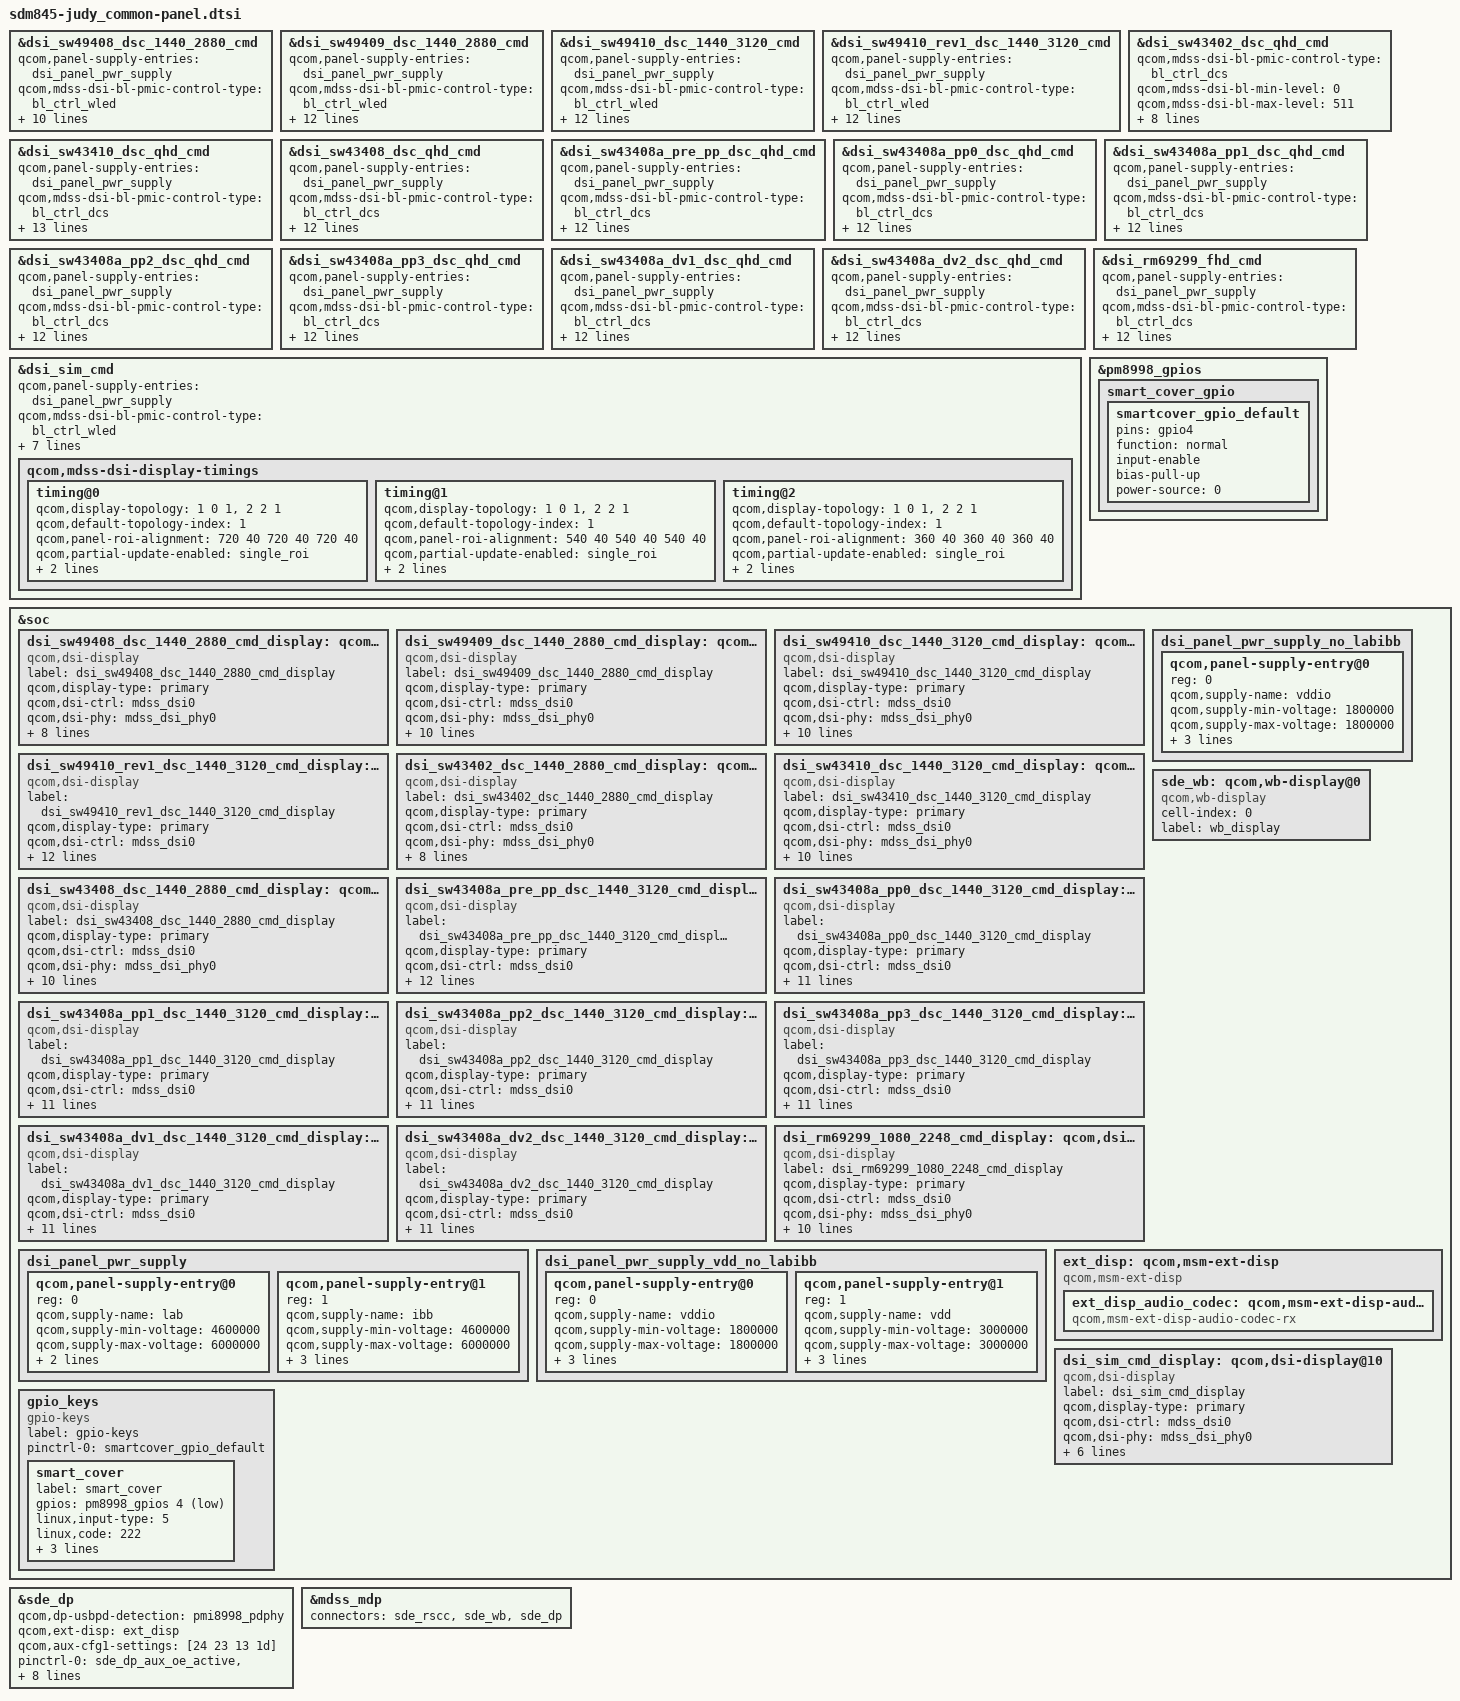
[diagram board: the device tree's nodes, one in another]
/* Copyright (c) 2017, The Linux Foundation. All rights reserved.
 *
 * This program is free software; you can redistribute it and/or modify
 * it under the terms of the GNU General Public License version 2 and
 * only version 2 as published by the Free Software Foundation.
 *
 * This program is distributed in the hope that it will be useful,
 * but WITHOUT ANY WARRANTY; without even the implied warranty of
 * MERCHANTABILITY or FITNESS FOR A PARTICULAR PURPOSE.  See the
 * GNU General Public License for more details.
 */

#include "../dsi-panel-sw49408-dsc-1440-2880-cmd.dtsi"
#include "../dsi-panel-sw49409-dsc-1440-2880-cmd.dtsi"
#include "../dsi-panel-sw49410-dsc-1440-3120-cmd.dtsi"
#include "../dsi-panel-sw49410-rev1-dsc-1440-3120-cmd.dtsi"
#include "../dsi-panel-sw43402-dsc-qhd-cmd.dtsi"
#include "../dsi-panel-sw43408-dsc-qhd-cmd.dtsi"
#include "../dsi-panel-sw43408a-pre-pp-dsc-qhd-cmd.dtsi"
#include "../dsi-panel-sw43408a-pp0-dsc-qhd-cmd.dtsi"
#include "../dsi-panel-sw43408a-pp1-dsc-qhd-cmd.dtsi"
#include "../dsi-panel-sw43408a-pp2-dsc-qhd-cmd.dtsi"
#include "../dsi-panel-sw43408a-pp3-dsc-qhd-cmd.dtsi"
#include "../dsi-panel-sw43408a-dv1-dsc-qhd-cmd.dtsi"
#include "../dsi-panel-sw43408a-dv2-dsc-qhd-cmd.dtsi"
#include "../dsi-panel-sw43410-dsc-qhd-cmd.dtsi"
#include "../dsi-panel-rm69299-fhd-cmd.dtsi"
#include "../../../qcom/dsi-panel-sim-cmd.dtsi"

#include <dt-bindings/clock/mdss-10nm-pll-clk.h>

&dsi_sw49408_dsc_1440_2880_cmd {
	qcom,panel-supply-entries = <&dsi_panel_pwr_supply>;
	qcom,mdss-dsi-bl-pmic-control-type = "bl_ctrl_wled";
	qcom,mdss-dsi-bl-min-level = <1>;
	qcom,mdss-dsi-bl-max-level = <4095>;
	qcom,platform-reset-gpio = <&tlmm 6 0>;
	lge,man-name = "LGD";
	lge,ddic-name = "sw49408";
	lge,panel-pins =
		<&tlmm 2 0>,  // vddio
		<&tlmm 116 0>; // vpnl
	lge,panel-on-pin-seq = <0 1 2>, <1 1 5>;
	lge,panel-off-pin-seq = <1 0 5>, <0 0 0>;
	lge,use-labibb;
	lge,default-brightness = <144>;
};

&dsi_sw49409_dsc_1440_2880_cmd {
	qcom,panel-supply-entries = <&dsi_panel_pwr_supply>;
	qcom,mdss-dsi-bl-pmic-control-type = "bl_ctrl_wled";
	qcom,mdss-dsi-bl-min-level = <1>;
	qcom,mdss-dsi-bl-max-level = <4095>;
	qcom,mdss-brightness-max-level = <255>;
	qcom,platform-reset-gpio = <&tlmm 6 0>;
	lge,panel-pins =
		<&tlmm 2 0>;  // vddio
	lge,man-name = "LGD";
	lge,ddic-name = "sw49409";
	lge,panel-on-pin-seq = <0 1 6>;
	lge,panel-off-pin-seq = <0 0 0>;
	lge,use-labibb;
	lge,reset-after-ddvd;
	lge,default-brightness = <144>;
};

&dsi_sw49410_dsc_1440_3120_cmd {
	qcom,panel-supply-entries = <&dsi_panel_pwr_supply>;
	qcom,mdss-dsi-bl-pmic-control-type = "bl_ctrl_wled";
	qcom,mdss-dsi-bl-min-level = <1>;
	qcom,mdss-dsi-bl-max-level = <4095>;
	qcom,mdss-brightness-max-level = <255>;
	qcom,platform-reset-gpio = <&tlmm 6 0>;
	lge,panel-pins =
		<&tlmm 2 0>;  // vddio
	lge,man-name = "LGD";
	lge,ddic-name = "sw49410";
	lge,panel-on-pin-seq = <0 1 6>;
	lge,panel-off-pin-seq = <0 0 0>;
	lge,use-labibb;
	lge,reset-after-ddvd;
	lge,default-brightness = <144>;
};

&dsi_sw49410_rev1_dsc_1440_3120_cmd {
	qcom,panel-supply-entries = <&dsi_panel_pwr_supply>;
	qcom,mdss-dsi-bl-pmic-control-type = "bl_ctrl_wled";
	qcom,mdss-dsi-bl-min-level = <1>;
	qcom,mdss-dsi-bl-max-level = <4095>;
	qcom,mdss-brightness-max-level = <255>;
	qcom,platform-reset-gpio = <&tlmm 6 0>;
	lge,panel-pins =
		<&tlmm 2 0>;  // vddio
	lge,man-name = "LGD";
	lge,ddic-name = "sw49410_rev1";
	lge,panel-on-pin-seq = <0 1 6>;
	lge,panel-off-pin-seq = <0 0 0>;
	lge,use-labibb;
	lge,reset-after-ddvd;
	lge,default-brightness = <144>;
};

&dsi_sw43402_dsc_qhd_cmd {
	qcom,mdss-dsi-bl-pmic-control-type = "bl_ctrl_dcs";
	qcom,mdss-dsi-bl-min-level = <0>;
	qcom,mdss-dsi-bl-max-level = <511>;
	qcom,mdss-brightness-max-level = <511>;
	qcom,platform-reset-gpio = <&tlmm 6 0>;
	lge,man-name = "LGD";
	lge,ddic-name = "sw43402";
	lge,panel-pins =
		<&tlmm 2 0>,  // vddio
		<&tlmm 113 0>; // vpnl
	lge,panel-on-pin-seq = <0 1 2>, <1 1 5>;
	lge,panel-off-pin-seq = <1 0 5>, <0 0 0>;
	lge,default-brightness = <158>;
};

&dsi_sw43410_dsc_qhd_cmd {
	qcom,panel-supply-entries = <&dsi_panel_pwr_supply>;
	qcom,mdss-dsi-bl-pmic-control-type = "bl_ctrl_dcs";
	qcom,mdss-dsi-bl-min-level = <10>;
	qcom,mdss-dsi-bl-max-level = <511>;
	qcom,mdss-brightness-max-level = <511>;
	qcom,platform-reset-gpio = <&tlmm 6 0>;
	lge,man-name = "LGD";
	lge,ddic-name = "sw43410";
	lge,panel-pins =
		<&tlmm 2 0>,  // vddio
		<&tlmm 113 0>; // vpnl
	lge,panel-on-pin-seq = <0 1 2>, <1 1 5>;
	lge,panel-off-pin-seq = <1 0 5>, <0 0 0>;
	lge,use-labibb;
	lge,dcs-brightness-bigendian;
	lge,reset-after-ddvd;
	lge,default-brightness = <158>;
};

&dsi_sw43408_dsc_qhd_cmd {
	qcom,panel-supply-entries = <&dsi_panel_pwr_supply>;
	qcom,mdss-dsi-bl-pmic-control-type = "bl_ctrl_dcs";
	qcom,mdss-dsi-bl-min-level = <10>;
	qcom,mdss-dsi-bl-max-level = <511>;
	qcom,mdss-brightness-max-level = <511>;
	qcom,platform-reset-gpio = <&tlmm 6 0>;
	lge,man-name = "LGD";
	lge,ddic-name = "sw43408";
	lge,panel-pins =
		<&tlmm 8 0>,  // vddio
		<&tlmm 113 0>; // vpnl
	lge,panel-on-pin-seq = <0 1 2>, <1 1 5>;
	lge,panel-off-pin-seq = <1 0 5>, <0 0 0>;
	lge,use-labibb;
	lge,dcs-brightness-bigendian;
	lge,default-brightness = <144>;
};

&dsi_sw43408a_pre_pp_dsc_qhd_cmd {
	qcom,panel-supply-entries = <&dsi_panel_pwr_supply>;
	qcom,mdss-dsi-bl-pmic-control-type = "bl_ctrl_dcs";
	qcom,mdss-dsi-bl-min-level = <10>;
	qcom,mdss-dsi-bl-max-level = <511>;
	qcom,mdss-brightness-max-level = <511>;
	qcom,platform-reset-gpio = <&tlmm 6 0>;
	lge,man-name = "LGD";
	lge,ddic-name = "sw43408a";
	lge,panel-pins =
		<&tlmm 2 0>,  // vddio
		<&tlmm 113 0>; // vpnl
	lge,panel-on-pin-seq = <0 1 2>, <1 1 5>;
	lge,panel-off-pin-seq = <1 0 5>, <0 0 0>;
	lge,use-labibb;
	lge,dcs-brightness-bigendian;
	lge,default-brightness = <144>;
};

&dsi_sw43408a_pp0_dsc_qhd_cmd {
	qcom,panel-supply-entries = <&dsi_panel_pwr_supply>;
	qcom,mdss-dsi-bl-pmic-control-type = "bl_ctrl_dcs";
	qcom,mdss-dsi-bl-min-level = <10>;
	qcom,mdss-dsi-bl-max-level = <511>;
	qcom,mdss-brightness-max-level = <511>;
	qcom,platform-reset-gpio = <&tlmm 6 0>;
	lge,man-name = "LGD";
	lge,ddic-name = "sw43408a";
	lge,panel-pins =
		<&tlmm 2 0>,  // vddio
		<&tlmm 113 0>; // vpnl
	lge,panel-on-pin-seq = <0 1 2>, <1 1 5>;
	lge,panel-off-pin-seq = <1 0 5>, <0 0 0>;
	lge,use-labibb;
	lge,dcs-brightness-bigendian;
	lge,default-brightness = <144>;
};

&dsi_sw43408a_pp1_dsc_qhd_cmd {
	qcom,panel-supply-entries = <&dsi_panel_pwr_supply>;
	qcom,mdss-dsi-bl-pmic-control-type = "bl_ctrl_dcs";
	qcom,mdss-dsi-bl-min-level = <10>;
	qcom,mdss-dsi-bl-max-level = <511>;
	qcom,mdss-brightness-max-level = <511>;
	qcom,platform-reset-gpio = <&tlmm 6 0>;
	lge,man-name = "LGD";
	lge,ddic-name = "sw43408a";
	lge,panel-pins =
		<&tlmm 2 0>,  // vddio
		<&tlmm 113 0>; // vpnl
	lge,panel-on-pin-seq = <0 1 2>, <1 1 5>;
	lge,panel-off-pin-seq = <1 0 5>, <0 0 0>;
	lge,use-labibb;
	lge,dcs-brightness-bigendian;
	lge,default-brightness = <144>;
};

&dsi_sw43408a_pp2_dsc_qhd_cmd {
	qcom,panel-supply-entries = <&dsi_panel_pwr_supply>;
	qcom,mdss-dsi-bl-pmic-control-type = "bl_ctrl_dcs";
	qcom,mdss-dsi-bl-min-level = <10>;
	qcom,mdss-dsi-bl-max-level = <511>;
	qcom,mdss-brightness-max-level = <511>;
	qcom,platform-reset-gpio = <&tlmm 6 0>;
	lge,man-name = "LGD";
	lge,ddic-name = "sw43408a";
	lge,panel-pins =
		<&tlmm 2 0>,  // vddio
		<&tlmm 113 0>; // vpnl
	lge,panel-on-pin-seq = <0 1 2>, <1 1 5>;
	lge,panel-off-pin-seq = <1 0 5>, <0 0 0>;
	lge,use-labibb;
	lge,dcs-brightness-bigendian;
	lge,default-brightness = <144>;
};

&dsi_sw43408a_pp3_dsc_qhd_cmd {
	qcom,panel-supply-entries = <&dsi_panel_pwr_supply>;
	qcom,mdss-dsi-bl-pmic-control-type = "bl_ctrl_dcs";
	qcom,mdss-dsi-bl-min-level = <10>;
	qcom,mdss-dsi-bl-max-level = <511>;
	qcom,mdss-brightness-max-level = <511>;
	qcom,platform-reset-gpio = <&tlmm 6 0>;
	lge,man-name = "LGD";
	lge,ddic-name = "sw43408a";
	lge,panel-pins =
		<&tlmm 2 0>,  // vddio
		<&tlmm 113 0>; // vpnl
	lge,panel-on-pin-seq = <0 1 2>, <1 1 5>;
	lge,panel-off-pin-seq = <1 0 5>, <0 0 0>;
	lge,use-labibb;
	lge,dcs-brightness-bigendian;
	lge,default-brightness = <144>;
};

&dsi_sw43408a_dv1_dsc_qhd_cmd {
	qcom,panel-supply-entries = <&dsi_panel_pwr_supply>;
	qcom,mdss-dsi-bl-pmic-control-type = "bl_ctrl_dcs";
	qcom,mdss-dsi-bl-min-level = <10>;
	qcom,mdss-dsi-bl-max-level = <511>;
	qcom,mdss-brightness-max-level = <511>;
	qcom,platform-reset-gpio = <&tlmm 6 0>;
	lge,man-name = "LGD";
	lge,ddic-name = "sw43408a";
	lge,panel-pins =
		<&tlmm 2 0>,  // vddio
		<&tlmm 113 0>; // vpnl
	lge,panel-on-pin-seq = <0 1 2>, <1 1 5>;
	lge,panel-off-pin-seq = <1 0 5>, <0 0 0>;
	lge,use-labibb;
	lge,dcs-brightness-bigendian;
	lge,default-brightness = <144>;
};

&dsi_sw43408a_dv2_dsc_qhd_cmd {
	qcom,panel-supply-entries = <&dsi_panel_pwr_supply>;
	qcom,mdss-dsi-bl-pmic-control-type = "bl_ctrl_dcs";
	qcom,mdss-dsi-bl-min-level = <10>;
	qcom,mdss-dsi-bl-max-level = <511>;
	qcom,mdss-brightness-max-level = <511>;
	qcom,platform-reset-gpio = <&tlmm 6 0>;
	lge,man-name = "LGD";
	lge,ddic-name = "sw43408a";
	lge,panel-pins =
		<&tlmm 2 0>,  // vddio
		<&tlmm 113 0>; // vpnl
	lge,panel-on-pin-seq = <0 1 2>, <1 1 5>;
	lge,panel-off-pin-seq = <1 0 5>, <0 0 0>;
	lge,use-labibb;
	lge,dcs-brightness-bigendian;
	lge,default-brightness = <144>;
};

&dsi_rm69299_fhd_cmd {
	qcom,panel-supply-entries = <&dsi_panel_pwr_supply>;
	qcom,mdss-dsi-bl-pmic-control-type = "bl_ctrl_dcs";
	qcom,mdss-dsi-bl-min-level = <10>;
	qcom,mdss-dsi-bl-max-level = <511>;
	qcom,mdss-brightness-max-level = <511>;
	qcom,platform-reset-gpio = <&tlmm 6 0>;
	lge,man-name = "TIANMA";
	lge,ddic-name = "rm69299";
	lge,panel-pins =
		<&tlmm 2 0>,  // vddio
		<&tlmm 113 0>; // vpnl
	lge,panel-on-pin-seq = <0 1 2>, <1 1 5>;
	lge,panel-off-pin-seq = <1 0 5>, <0 0 0>;
	lge,use-labibb;
	lge,dcs-brightness-bigendian;
	lge,default-brightness = <144>;
};

&dsi_sim_cmd {
	qcom,panel-supply-entries = <&dsi_panel_pwr_supply>;
	qcom,mdss-dsi-bl-pmic-control-type = "bl_ctrl_wled";
	qcom,platform-reset-gpio = <&tlmm 6 0>;

	qcom,mdss-dsi-t-clk-post = <0x0c>;
	qcom,mdss-dsi-t-clk-pre = <0x29>;

	lge,ddic-name = "qcom simulation panel";
	lge,panel-pins =
		<&tlmm 2 0>,  // vddio
		<&tlmm 116 0>; // vpnl
	lge,panel-on-pin-seq = <0 1 2>, <1 1 5>;
	lge,panel-off-pin-seq = <1 0 5>, <0 0 0>;

	qcom,mdss-dsi-display-timings {
		timing@0{
			qcom,display-topology = <1 0 1>, <2 2 1>;
			qcom,default-topology-index = <1>;
			qcom,panel-roi-alignment = <720 40 720 40 720 40>;
			qcom,partial-update-enabled = "single_roi";
			qcom,mdss-dsi-panel-phy-timings = [00 1a 06 06 22 20 07
					07 04 03 04 00];
		};
		timing@1{
			qcom,display-topology = <1 0 1>, <2 2 1>;
			qcom,default-topology-index = <1>;
			qcom,panel-roi-alignment = <540 40 540 40 540 40>;
			qcom,partial-update-enabled = "single_roi";
			qcom,mdss-dsi-panel-phy-timings = [00 1a 06 06 22 20 07
					07 04 03 04 00];
		};
		timing@2{
			qcom,display-topology = <1 0 1>, <2 2 1>;
			qcom,default-topology-index = <1>;
			qcom,panel-roi-alignment = <360 40 360 40 360 40>;
			qcom,partial-update-enabled = "single_roi";
			qcom,mdss-dsi-panel-phy-timings = [00 1a 06 06 22 20 07
					07 04 03 04 00];
		};
	};
};

&pm8998_gpios {
	smart_cover_gpio {
		 smartcover_gpio_default: smartcover_gpio_default {
			pins = "gpio4";
			function = "normal";
			input-enable;
			bias-pull-up;
			power-source = <0>;
		};
	};
};

&soc {
	dsi_sw49408_dsc_1440_2880_cmd_display: qcom,dsi-display@12 {
		compatible = "qcom,dsi-display";
		label = "dsi_sw49408_dsc_1440_2880_cmd_display";
		qcom,display-type = "primary";

		qcom,dsi-ctrl = <&mdss_dsi0>;
		qcom,dsi-phy = <&mdss_dsi_phy0>;
		clocks = <&mdss_dsi0_pll BYTECLK_MUX_0_CLK>,
			<&mdss_dsi0_pll PCLK_MUX_0_CLK>;
		clock-names = "mux_byte_clk", "mux_pixel_clk";

		pinctrl-names = "panel_active", "panel_suspend";
		pinctrl-0 = <&sde_dsi_active &sde_te_active>;
		pinctrl-1 = <&sde_dsi_suspend &sde_te_suspend>;

		qcom,dsi-panel = <&dsi_sw49408_dsc_1440_2880_cmd>;
		lab-supply = <&lab_regulator>;
		ibb-supply = <&ibb_regulator>;
		qcom,platform-te-gpio = <&tlmm 10 0>;
	};

	dsi_sw49409_dsc_1440_2880_cmd_display: qcom,dsi-display@13 {
		compatible = "qcom,dsi-display";
		label = "dsi_sw49409_dsc_1440_2880_cmd_display";
		qcom,display-type = "primary";

		qcom,dsi-ctrl = <&mdss_dsi0>;
		qcom,dsi-phy = <&mdss_dsi_phy0>;
		clocks = <&mdss_dsi0_pll BYTECLK_MUX_0_CLK>,
			<&mdss_dsi0_pll PCLK_MUX_0_CLK>;
		clock-names = "mux_byte_clk", "mux_pixel_clk";

		pinctrl-names = "panel_active", "panel_suspend";
		pinctrl-0 = <&sde_dsi_active &sde_te_active &extra_ldo_panel_power_active>;
		pinctrl-1 = <&sde_dsi_suspend &sde_te_suspend &extra_ldo_panel_power_suspend>;

		qcom,dsi-panel = <&dsi_sw49409_dsc_1440_2880_cmd>;
		lab-supply = <&lab_regulator>;
		ibb-supply = <&ibb_regulator>;
		qcom,platform-te-gpio = <&tlmm 10 0>;
	};

	dsi_sw49410_dsc_1440_3120_cmd_display: qcom,dsi-display@18 {
		compatible = "qcom,dsi-display";
		label = "dsi_sw49410_dsc_1440_3120_cmd_display";
		qcom,display-type = "primary";

		qcom,dsi-ctrl = <&mdss_dsi0>;
		qcom,dsi-phy = <&mdss_dsi_phy0>;
		clocks = <&mdss_dsi0_pll BYTECLK_MUX_0_CLK>,
			<&mdss_dsi0_pll PCLK_MUX_0_CLK>;
		clock-names = "mux_byte_clk", "mux_pixel_clk";

		pinctrl-names = "panel_active", "panel_suspend";
		pinctrl-0 = <&sde_dsi_active &sde_te_active &extra_ldo_panel_power_active>;
		pinctrl-1 = <&sde_dsi_suspend &sde_te_suspend &extra_ldo_panel_power_suspend>;

		qcom,dsi-panel = <&dsi_sw49410_dsc_1440_3120_cmd>;
		lab-supply = <&lab_regulator>;
		ibb-supply = <&ibb_regulator>;
		qcom,platform-te-gpio = <&tlmm 10 0>;
	};

	dsi_sw49410_rev1_dsc_1440_3120_cmd_display: qcom,dsi-display@20 {
		compatible = "qcom,dsi-display";
		label = "dsi_sw49410_rev1_dsc_1440_3120_cmd_display";
		qcom,display-type = "primary";

		qcom,dsi-ctrl = <&mdss_dsi0>;
		qcom,dsi-phy = <&mdss_dsi_phy0>;
		clocks = <&mdss_dsi0_pll BYTECLK_MUX_0_CLK>,
			<&mdss_dsi0_pll PCLK_MUX_0_CLK>;
		clock-names = "mux_byte_clk", "mux_pixel_clk";

		pinctrl-names = "panel_active", "panel_suspend";
		pinctrl-0 = <&sde_dsi_active &sde_te_active &extra_ldo_panel_power_active>;
		pinctrl-1 = <&sde_dsi_suspend &sde_te_suspend &extra_ldo_panel_power_suspend>;

		qcom,dsi-panel = <&dsi_sw49410_rev1_dsc_1440_3120_cmd>;
		lab-supply = <&lab_regulator>;
		ibb-supply = <&ibb_regulator>;
		qcom,platform-te-gpio = <&tlmm 10 0>;
	};

	dsi_sw43402_dsc_1440_2880_cmd_display: qcom,dsi-display@14 {
		compatible = "qcom,dsi-display";
		label = "dsi_sw43402_dsc_1440_2880_cmd_display";
		qcom,display-type = "primary";

		qcom,dsi-ctrl = <&mdss_dsi0>;
		qcom,dsi-phy = <&mdss_dsi_phy0>;
		clocks = <&mdss_dsi0_pll BYTECLK_MUX_0_CLK>,
			<&mdss_dsi0_pll PCLK_MUX_0_CLK>;
		clock-names = "mux_byte_clk", "mux_pixel_clk";

		pinctrl-names = "panel_active", "panel_suspend";
		pinctrl-0 = <&sde_dsi_active &sde_te_active &extra_ldo_panel_power_active>;
		pinctrl-1 = <&sde_dsi_suspend &sde_te_suspend &extra_ldo_panel_power_suspend>;
		qcom,dsi-panel = <&dsi_sw43402_dsc_qhd_cmd>;
		qcom,platform-te-gpio = <&tlmm 10 0>;
	};

	dsi_sw43410_dsc_1440_3120_cmd_display: qcom,dsi-display@15 {
		compatible = "qcom,dsi-display";
		label = "dsi_sw43410_dsc_1440_3120_cmd_display";
		qcom,display-type = "primary";

		qcom,dsi-ctrl = <&mdss_dsi0>;
		qcom,dsi-phy = <&mdss_dsi_phy0>;
		clocks = <&mdss_dsi0_pll BYTECLK_MUX_0_CLK>,
			<&mdss_dsi0_pll PCLK_MUX_0_CLK>;
		clock-names = "mux_byte_clk", "mux_pixel_clk";

		pinctrl-names = "panel_active", "panel_suspend";
		pinctrl-0 = <&sde_dsi_active &sde_te_active &extra_ldo_panel_power_active>;
		pinctrl-1 = <&sde_dsi_suspend &sde_te_suspend &extra_ldo_panel_power_suspend>;
		qcom,dsi-panel = <&dsi_sw43410_dsc_qhd_cmd>;
		lab-supply = <&lab_regulator>;
		ibb-supply = <&ibb_regulator>;
		qcom,platform-te-gpio = <&tlmm 10 0>;
	};

	dsi_sw43408_dsc_1440_2880_cmd_display: qcom,dsi-display@16 {
		compatible = "qcom,dsi-display";
		label = "dsi_sw43408_dsc_1440_2880_cmd_display";
		qcom,display-type = "primary";

		qcom,dsi-ctrl = <&mdss_dsi0>;
		qcom,dsi-phy = <&mdss_dsi_phy0>;
		clocks = <&mdss_dsi0_pll BYTECLK_MUX_0_CLK>,
			<&mdss_dsi0_pll PCLK_MUX_0_CLK>;
		clock-names = "mux_byte_clk", "mux_pixel_clk";

		pinctrl-names = "panel_active", "panel_suspend";
		pinctrl-0 = <&sde_dsi_active &sde_te_active &extra_ldo_panel_power_active>;
		pinctrl-1 = <&sde_dsi_suspend &sde_te_suspend &extra_ldo_panel_power_suspend>;
		qcom,dsi-panel = <&dsi_sw43408_dsc_qhd_cmd>;
		lab-supply = <&lab_regulator>;
		ibb-supply = <&ibb_regulator>;
		qcom,platform-te-gpio = <&tlmm 10 0>;
	};

	dsi_sw43408a_pre_pp_dsc_1440_3120_cmd_display: qcom,dsi-display@19 {
		compatible = "qcom,dsi-display";
		label = "dsi_sw43408a_pre_pp_dsc_1440_3120_cmd_display";
		qcom,display-type = "primary";

		qcom,dsi-ctrl = <&mdss_dsi0>;
		qcom,dsi-phy = <&mdss_dsi_phy0>;
		clocks = <&mdss_dsi0_pll BYTECLK_MUX_0_CLK>,
			<&mdss_dsi0_pll PCLK_MUX_0_CLK>;
		clock-names = "mux_byte_clk", "mux_pixel_clk";

		pinctrl-names = "panel_active", "panel_suspend";
		pinctrl-0 = <&sde_dsi_active &sde_te_active &extra_ldo_panel_power_active>;
		pinctrl-1 = <&sde_dsi_suspend &sde_te_suspend &extra_ldo_panel_power_suspend>;
		qcom,dsi-panel = <&dsi_sw43408a_pre_pp_dsc_qhd_cmd>;
		lab-supply = <&lab_regulator>;
		ibb-supply = <&ibb_regulator>;
		qcom,platform-te-gpio = <&tlmm 10 0>;
	};

	dsi_sw43408a_pp0_dsc_1440_3120_cmd_display: qcom,dsi-display@21 {
		compatible = "qcom,dsi-display";
		label = "dsi_sw43408a_pp0_dsc_1440_3120_cmd_display";
		qcom,display-type = "primary";

		qcom,dsi-ctrl = <&mdss_dsi0>;
		qcom,dsi-phy = <&mdss_dsi_phy0>;
		clocks = <&mdss_dsi0_pll BYTECLK_MUX_0_CLK>,
			<&mdss_dsi0_pll PCLK_MUX_0_CLK>;
		clock-names = "mux_byte_clk", "mux_pixel_clk";

		pinctrl-names = "panel_active", "panel_suspend";
		pinctrl-0 = <&sde_dsi_active &sde_te_active &extra_ldo_panel_power_active>;
		pinctrl-1 = <&sde_dsi_suspend &sde_te_suspend &extra_ldo_panel_power_suspend>;
		qcom,dsi-panel = <&dsi_sw43408a_pp0_dsc_qhd_cmd>;
		lab-supply = <&lab_regulator>;
		ibb-supply = <&ibb_regulator>;
		qcom,platform-te-gpio = <&tlmm 10 0>;
	};

	dsi_sw43408a_pp1_dsc_1440_3120_cmd_display: qcom,dsi-display@22 {
		compatible = "qcom,dsi-display";
		label = "dsi_sw43408a_pp1_dsc_1440_3120_cmd_display";
		qcom,display-type = "primary";

		qcom,dsi-ctrl = <&mdss_dsi0>;
		qcom,dsi-phy = <&mdss_dsi_phy0>;
		clocks = <&mdss_dsi0_pll BYTECLK_MUX_0_CLK>,
			<&mdss_dsi0_pll PCLK_MUX_0_CLK>;
		clock-names = "mux_byte_clk", "mux_pixel_clk";

		pinctrl-names = "panel_active", "panel_suspend";
		pinctrl-0 = <&sde_dsi_active &sde_te_active &extra_ldo_panel_power_active>;
		pinctrl-1 = <&sde_dsi_suspend &sde_te_suspend &extra_ldo_panel_power_suspend>;
		qcom,dsi-panel = <&dsi_sw43408a_pp1_dsc_qhd_cmd>;
		lab-supply = <&lab_regulator>;
		ibb-supply = <&ibb_regulator>;
		qcom,platform-te-gpio = <&tlmm 10 0>;
	};

	dsi_sw43408a_pp2_dsc_1440_3120_cmd_display: qcom,dsi-display@23 {
		compatible = "qcom,dsi-display";
		label = "dsi_sw43408a_pp2_dsc_1440_3120_cmd_display";
		qcom,display-type = "primary";

		qcom,dsi-ctrl = <&mdss_dsi0>;
		qcom,dsi-phy = <&mdss_dsi_phy0>;
		clocks = <&mdss_dsi0_pll BYTECLK_MUX_0_CLK>,
			<&mdss_dsi0_pll PCLK_MUX_0_CLK>;
		clock-names = "mux_byte_clk", "mux_pixel_clk";

		pinctrl-names = "panel_active", "panel_suspend";
		pinctrl-0 = <&sde_dsi_active &sde_te_active &extra_ldo_panel_power_active>;
		pinctrl-1 = <&sde_dsi_suspend &sde_te_suspend &extra_ldo_panel_power_suspend>;
		qcom,dsi-panel = <&dsi_sw43408a_pp2_dsc_qhd_cmd>;
		lab-supply = <&lab_regulator>;
		ibb-supply = <&ibb_regulator>;
		qcom,platform-te-gpio = <&tlmm 10 0>;
	};

	dsi_sw43408a_pp3_dsc_1440_3120_cmd_display: qcom,dsi-display@24 {
		compatible = "qcom,dsi-display";
		label = "dsi_sw43408a_pp3_dsc_1440_3120_cmd_display";
		qcom,display-type = "primary";

		qcom,dsi-ctrl = <&mdss_dsi0>;
		qcom,dsi-phy = <&mdss_dsi_phy0>;
		clocks = <&mdss_dsi0_pll BYTECLK_MUX_0_CLK>,
			<&mdss_dsi0_pll PCLK_MUX_0_CLK>;
		clock-names = "mux_byte_clk", "mux_pixel_clk";

		pinctrl-names = "panel_active", "panel_suspend";
		pinctrl-0 = <&sde_dsi_active &sde_te_active &extra_ldo_panel_power_active>;
		pinctrl-1 = <&sde_dsi_suspend &sde_te_suspend &extra_ldo_panel_power_suspend>;
		qcom,dsi-panel = <&dsi_sw43408a_pp3_dsc_qhd_cmd>;
		lab-supply = <&lab_regulator>;
		ibb-supply = <&ibb_regulator>;
		qcom,platform-te-gpio = <&tlmm 10 0>;
	};

	dsi_sw43408a_dv1_dsc_1440_3120_cmd_display: qcom,dsi-display@25 {
		compatible = "qcom,dsi-display";
		label = "dsi_sw43408a_dv1_dsc_1440_3120_cmd_display";
		qcom,display-type = "primary";

		qcom,dsi-ctrl = <&mdss_dsi0>;
		qcom,dsi-phy = <&mdss_dsi_phy0>;
		clocks = <&mdss_dsi0_pll BYTECLK_MUX_0_CLK>,
			<&mdss_dsi0_pll PCLK_MUX_0_CLK>;
		clock-names = "mux_byte_clk", "mux_pixel_clk";

		pinctrl-names = "panel_active", "panel_suspend";
		pinctrl-0 = <&sde_dsi_active &sde_te_active &extra_ldo_panel_power_active>;
		pinctrl-1 = <&sde_dsi_suspend &sde_te_suspend &extra_ldo_panel_power_suspend>;
		qcom,dsi-panel = <&dsi_sw43408a_dv1_dsc_qhd_cmd>;
		lab-supply = <&lab_regulator>;
		ibb-supply = <&ibb_regulator>;
		qcom,platform-te-gpio = <&tlmm 10 0>;
	};

	dsi_sw43408a_dv2_dsc_1440_3120_cmd_display: qcom,dsi-display@26 {
		compatible = "qcom,dsi-display";
		label = "dsi_sw43408a_dv2_dsc_1440_3120_cmd_display";
		qcom,display-type = "primary";

		qcom,dsi-ctrl = <&mdss_dsi0>;
		qcom,dsi-phy = <&mdss_dsi_phy0>;
		clocks = <&mdss_dsi0_pll BYTECLK_MUX_0_CLK>,
			<&mdss_dsi0_pll PCLK_MUX_0_CLK>;
		clock-names = "mux_byte_clk", "mux_pixel_clk";

		pinctrl-names = "panel_active", "panel_suspend";
		pinctrl-0 = <&sde_dsi_active &sde_te_active &extra_ldo_panel_power_active>;
		pinctrl-1 = <&sde_dsi_suspend &sde_te_suspend &extra_ldo_panel_power_suspend>;
		qcom,dsi-panel = <&dsi_sw43408a_dv2_dsc_qhd_cmd>;
		lab-supply = <&lab_regulator>;
		ibb-supply = <&ibb_regulator>;
		qcom,platform-te-gpio = <&tlmm 10 0>;
	};

	dsi_rm69299_1080_2248_cmd_display: qcom,dsi-display@27 {
		compatible = "qcom,dsi-display";
		label = "dsi_rm69299_1080_2248_cmd_display";
		qcom,display-type = "primary";

		qcom,dsi-ctrl = <&mdss_dsi0>;
		qcom,dsi-phy = <&mdss_dsi_phy0>;
		clocks = <&mdss_dsi0_pll BYTECLK_MUX_0_CLK>,
			<&mdss_dsi0_pll PCLK_MUX_0_CLK>;
		clock-names = "mux_byte_clk", "mux_pixel_clk";

		pinctrl-names = "panel_active", "panel_suspend";
		pinctrl-0 = <&sde_dsi_active &sde_te_active &extra_ldo_panel_power_active>;
		pinctrl-1 = <&sde_dsi_suspend &sde_te_suspend &extra_ldo_panel_power_suspend>;
		qcom,dsi-panel = <&dsi_rm69299_fhd_cmd>;
		lab-supply = <&lab_regulator>;
		ibb-supply = <&ibb_regulator>;
		qcom,platform-te-gpio = <&tlmm 10 0>;
	};

	dsi_panel_pwr_supply: dsi_panel_pwr_supply {
		#address-cells = <1>;
		#size-cells = <0>;

		qcom,panel-supply-entry@0 {
			reg = <0>;
			qcom,supply-name = "lab";
			qcom,supply-min-voltage = <4600000>;
			qcom,supply-max-voltage = <6000000>;
			qcom,supply-enable-load = <100000>;
			qcom,supply-disable-load = <100>;
		};

		qcom,panel-supply-entry@1 {
			reg = <1>;
			qcom,supply-name = "ibb";
			qcom,supply-min-voltage = <4600000>;
			qcom,supply-max-voltage = <6000000>;
			qcom,supply-enable-load = <100000>;
			qcom,supply-disable-load = <100>;
			qcom,supply-post-on-sleep = <20>;
		};
	};

	dsi_panel_pwr_supply_no_labibb: dsi_panel_pwr_supply_no_labibb {
		#address-cells = <1>;
		#size-cells = <0>;

		qcom,panel-supply-entry@0 {
			reg = <0>;
			qcom,supply-name = "vddio";
			qcom,supply-min-voltage = <1800000>;
			qcom,supply-max-voltage = <1800000>;
			qcom,supply-enable-load = <62000>;
			qcom,supply-disable-load = <80>;
			qcom,supply-post-on-sleep = <20>;
		};
	};

	dsi_panel_pwr_supply_vdd_no_labibb: dsi_panel_pwr_supply_vdd_no_labibb {
		#address-cells = <1>;
		#size-cells = <0>;

		qcom,panel-supply-entry@0 {
			reg = <0>;
			qcom,supply-name = "vddio";
			qcom,supply-min-voltage = <1800000>;
			qcom,supply-max-voltage = <1800000>;
			qcom,supply-enable-load = <62000>;
			qcom,supply-disable-load = <80>;
			qcom,supply-post-on-sleep = <20>;
		};

		qcom,panel-supply-entry@1 {
			reg = <1>;
			qcom,supply-name = "vdd";
			qcom,supply-min-voltage = <3000000>;
			qcom,supply-max-voltage = <3000000>;
			qcom,supply-enable-load = <857000>;
			qcom,supply-disable-load = <0>;
			qcom,supply-post-on-sleep = <0>;
		};
	};

	sde_wb: qcom,wb-display@0 {
		compatible = "qcom,wb-display";
		cell-index = <0>;
		label = "wb_display";
	};

	ext_disp: qcom,msm-ext-disp {
		compatible = "qcom,msm-ext-disp";

		ext_disp_audio_codec: qcom,msm-ext-disp-audio-codec-rx {
			compatible = "qcom,msm-ext-disp-audio-codec-rx";
		};
	};

	dsi_sim_cmd_display: qcom,dsi-display@10 {
		compatible = "qcom,dsi-display";
		label = "dsi_sim_cmd_display";
		qcom,display-type = "primary";

		qcom,dsi-ctrl = <&mdss_dsi0>;
		qcom,dsi-phy = <&mdss_dsi_phy0>;
		clocks = <&mdss_dsi0_pll BYTECLK_MUX_0_CLK>,
			<&mdss_dsi0_pll PCLK_MUX_0_CLK>;
		clock-names = "mux_byte_clk", "mux_pixel_clk";

		pinctrl-names = "panel_active", "panel_suspend";
		pinctrl-0 = <&sde_dsi_active &sde_te_active>;
		pinctrl-1 = <&sde_dsi_suspend &sde_te_suspend>;

		qcom,dsi-panel = <&dsi_sim_cmd>;
	};

	gpio_keys {
		compatible = "gpio-keys";
		label = "gpio-keys";
		status = "okay";

		pinctrl-names = "default";
		pinctrl-0 = <&smartcover_gpio_default>;

		smart_cover {
			label = "smart_cover";
			gpios = <&pm8998_gpios 4 GPIO_ACTIVE_LOW>;
			linux,input-type = <5>;
			linux,code = <222>;
			gpio-key,wakeup;
			debounce-interval = <15>;
			linux,can-disable;
		};
	};
};

&sde_dp {
	qcom,dp-usbpd-detection = <&pmi8998_pdphy>;
	qcom,ext-disp = <&ext_disp>;
	qcom,aux-cfg1-settings = [24 23 13 1d];

	pinctrl-names = "mdss_dp_active", "mdss_dp_sleep";
	pinctrl-0 = <&sde_dp_aux_oe_active &sde_dp_aux_sel_active  &sde_dp_usbplug_cc_active>;
	pinctrl-1 = <&sde_dp_aux_oe_suspend &sde_dp_aux_sel_suspend &sde_dp_usbplug_cc_suspend>;
	qcom,aux-en-gpio = <&tlmm 43 0>;
	qcom,aux-sel-gpio = <&tlmm 69 0>;
	qcom,usbplug-cc-gpio = <&tlmm 38 0>;
};
&mdss_mdp {

//	connectors = <&sde_rscc &sde_wb &dsi_sw49408_dsc_1440_2880_cmd_display>; /* LCD panel for HDK */
	connectors = <&sde_rscc &sde_wb &sde_dp>; /* OLED Panel for Real Board */
};

&dsi_sw49408_dsc_1440_2880_cmd_display {
//	qcom,dsi-display-active;
};

&dsi_sw49409_dsc_1440_2880_cmd_display {
//	qcom,dsi-display-active;
};

&dsi_sw43402_dsc_1440_2880_cmd_display {
//	qcom,dsi-display-active;
};

&dsi_sw43410_dsc_1440_3120_cmd_display {
//	qcom,dsi-display-active;
};

&dsi_sw43408_dsc_1440_2880_cmd_display {
//	qcom,dsi-display-active;
};

&dsi_sw43408a_pre_pp_dsc_1440_3120_cmd_display {
//	qcom,dsi-display-active;
};

&dsi_sw43408a_pp0_dsc_1440_3120_cmd_display {
//	qcom,dsi-display-active;
};

&dsi_sw43408a_pp1_dsc_1440_3120_cmd_display {
//	qcom,dsi-display-active;
};

&dsi_sw43408a_pp2_dsc_1440_3120_cmd_display {
//	qcom,dsi-display-active;
};

&dsi_sw43408a_pp3_dsc_1440_3120_cmd_display {
//	qcom,dsi-display-active;
};

&dsi_sw43408a_dv1_dsc_1440_3120_cmd_display {
//	qcom,dsi-display-active;
};

&dsi_sw43408a_dv2_dsc_1440_3120_cmd_display {
//	qcom,dsi-display-active;
};

&dsi_rm69299_1080_2248_cmd_display {
//	qcom,dsi-display-active;
};

&dsi_sim_cmd_display {
	qcom,dsi-display-active;
};
